AUTOSAR XML (schema 4-2-2)
package /Components
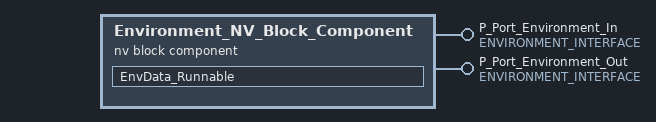
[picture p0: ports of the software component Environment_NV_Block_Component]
  nv block sw component type Environment_NV_Block_Component
    provide port P_Port_Environment_In: provided-interface=ENVIRONMENT_INTERFACE
    provide port P_Port_Environment_Out: provided-interface=ENVIRONMENT_INTERFACE
    behavior Environment_NV_Block_Behavior: handle-termination-and-restart=true
      init event Init_E: start-on-event=EnvData_Runnable
      runnable EnvData_Runnable: symbol=ENV_BLOCK_ENV_SYMBOL
        data-receive-point-by-arguments:
          access ENV_Input: accessed-variable=P_Port_Environment_In.ENVIRONMENT_DATA
        data-send-points:
          access ENV_Output: accessed-variable=P_Port_Environment_Out.ENVIRONMENT_DATA
